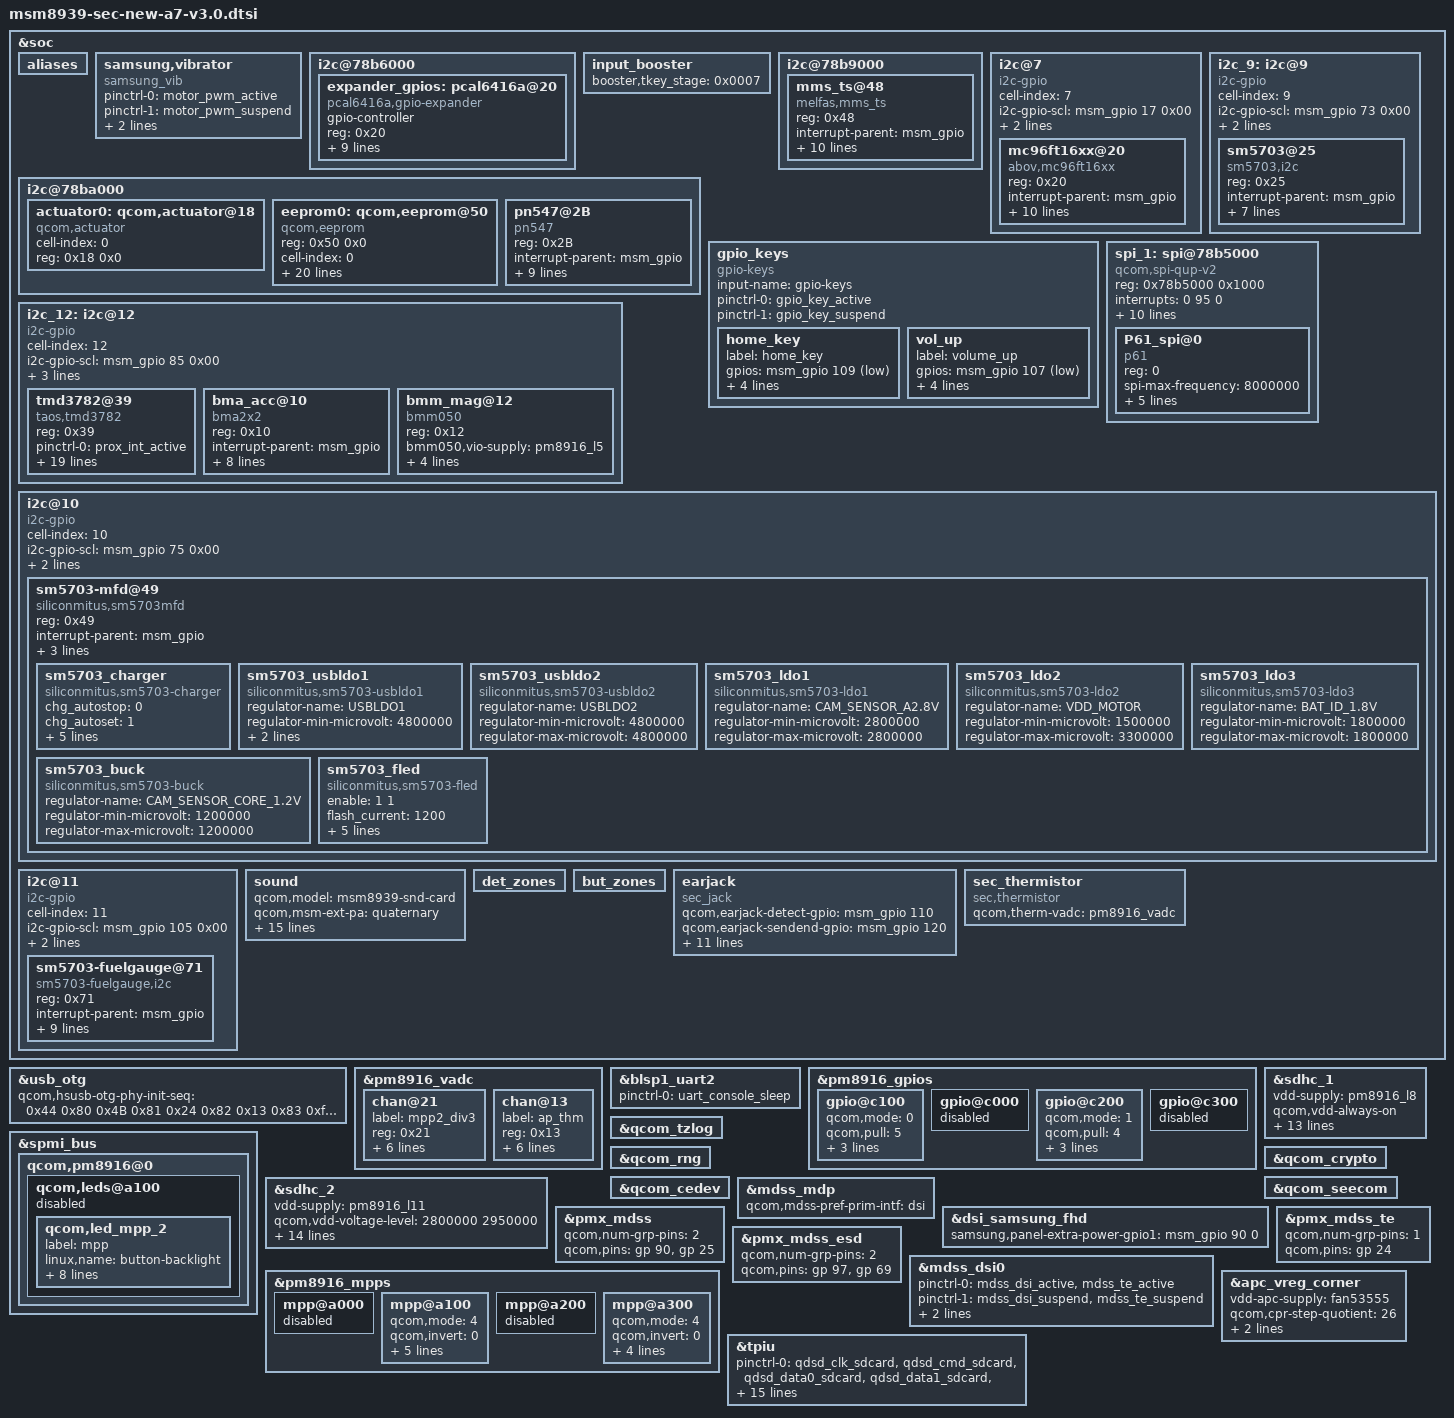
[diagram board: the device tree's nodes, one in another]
/* Copyright (c) 2014, The Linux Foundation. All rights reserved.
 *
 * This program is free software; you can redistribute it and/or modify
 * it under the terms of the GNU General Public License version 2 and
 * only version 2 as published by the Free Software Foundation.
 *
 * This program is distributed in the hope that it will be useful,
 * but WITHOUT ANY WARRANTY; without even the implied warranty of
 * MERCHANTABILITY or FITNESS FOR A PARTICULAR PURPOSE.  See the
 * GNU General Public License for more details.
 */

#include "msm8939-pinctrl-sec-a7-new-r00.dtsi"
#include "msm8939-camera.dtsi"
#include "msm8939-camera-sensor-cdp-a8-r07.dtsi"
#include "msm8939-sec-a7x-chn-battery-r00.dtsi"
#include "../../../../../../drivers/video/msm/mdss/samsung/S6E3FA3_AMS568HN01/dsi_panel_S6E3FA3_AMS568HN01_fhd_octa_cmd.dtsi"
#include "msm8939-a8lte_fingerprint-sensor_00.dtsi"

&soc {
	aliases {
	};

	samsung,vibrator {
		compatible = "samsung_vib";
		pinctrl-names = "tlmm_motor_active","tlmm_motor_suspend";
		pinctrl-0 = <&motor_pwm_active>;
		pinctrl-1 = <&motor_pwm_suspend>;
		samsung,vib_en = <&expander_gpios 15 0x1>;
		samsung,vib_pwm = <&msm_gpio 50 0x1>;
		status = "ok";
	};

	i2c@78b6000 { /* BLSP1 QUP2 */
		expander_gpios: pcal6416a@20 {
			compatible = "pcal6416a,gpio-expander";
			gpio-controller;
			#gpio-cells = <2>;
			reg = <0x20>;
			pinctrl-names = "expander_reset_setting";
			pinctrl-0 = <&expander_reset_active>;
			pcal6416a,gpio_start = <300>;
			pcal6416a,ngpio = <16>;
			pcal6416a,reset-gpio = <&msm_gpio 35 0x00>;
			pcal6416a,vdd-supply = <&pm8916_l5>;
			pcal6416a,support_initialize = <1>;
			/* config, 15 ~ 0, 1bit configure[1:input, 0:output]*/
			pcal6416a,config = <0x5FF0>;    /* 0101 1111 1111 0000 */
			/* data_out, 15 ~ 0, 1bit configure[1:high, 0:low]*/
			pcal6416a,data_out = <0x0004>;  /* 0000 0000 0000 0100  */
			/* pull_reg, 31 ~ 0, 2bit configure[00:no_pull, 01:pull_down, 10:pull_up, 11:not used]*/
			pcal6416a,pull_reg = <0x04000045>; /* 00 00 01 00 / 00 00 00 00 /  00 00 00 00 / 01 00 01 01 */
		};
	};

	input_booster {
		status = "okay";
		booster,tkey_stage = <0x0007>;
	};

	i2c@78b9000 { /* BLSP1 QUP5 */
		mms_ts@48 {
			compatible = "melfas,mms_ts";
			reg = <0x48>; /*slave address*/
			interrupt-parent = <&msm_gpio>;
			interrupts = <13 0>; /* Touch int gpio */
			pinctrl-names = "tsp_gpio_active", "tsp_gpio_suspend";
			pinctrl-0 = <&i2c_5_active &tsp_irq_default>;
			pinctrl-1 = <&i2c_5_sleep>;
			vdd-io-supply = <&pm8916_l6>;
			melfas,vdd_en = <&msm_gpio 89 0x1>;
			//melfas,io_en = <&msm_gpio 95 0x1>;
			melfas,irq-gpio = <&msm_gpio 13 0x00>; /*TSP IRQ GPIO */
			melfas,sda-gpio = <&msm_gpio 18 0x00>;
			melfas,scl-gpio = <&msm_gpio 19 0x00>;
			melfas,max_x = <2160>; /* <1080>; max x*/
			melfas,max_y = <3840>; /* <1920>; max y*/
		};
	};

	i2c@7 {
		cell-index = <7>;
                compatible = "i2c-gpio";
                i2c-gpio-scl = <&msm_gpio 17 0x00>;
                i2c-gpio-sda = <&msm_gpio 16 0x00>;
                i2c-gpio,delay-us = <5>;
                #address-cells = <1>;
                #size-cells = <0>;
		mc96ft16xx@20{
			compatible = "abov,mc96ft16xx";
			reg = <0x20>;
			interrupt-parent = <&msm_gpio>;
			interrupts = <114 0>;
			pinctrl-names = "touchkey_active", "touchkey_suspend";
			pinctrl-0 = <&touchkey_i2c_active &touchkey_int_active>;
			pinctrl-1 = <&touchkey_i2c_suspend &touchkey_int_suspend>;
			abov,sda-gpio = <&msm_gpio 16 0>;
			abov,scl-gpio = <&msm_gpio 17 0>;
			abov,irq-gpio = <&msm_gpio 114 0>;
			abov,tkey_en-gpio = <&msm_gpio 116 0>;
			//abov,tkey_led_en-gpio = <&msm_gpio 91 0>;
			vddo-supply = <&pm8916_l6>;
		};
	};

	i2c@78ba000 { /* BLSP1 QUP6 */
		status = "ok";

		actuator0: qcom,actuator@18 {
                        compatible = "qcom,actuator";
                        cell-index = <0>;
                        reg = <0x18 0x0>;
		};
                eeprom0: qcom,eeprom@50 {
                        compatible = "qcom,eeprom";
                        reg = <0x50 0x0>;
                        cell-index = <0>;
                        qcom,slave-addr = <0xB0>;
                        qcom,eeprom-name = "dw_dw9806b";
                        cam_vio-supply = <&pm8916_l16>;
                        qcom,cam-vreg-name = "cam_vio", "cam_vaf";
                        qcom,cam-vreg-type = <0 0>;
                        qcom,cam-vreg-min-voltage = <1800000 2800000>;
                        qcom,cam-vreg-max-voltage = <1800000 2800000>;
                        qcom,cam-vreg-op-mode = <1800000 100000>;
                        qcom,pvdd_is_en = <1>;
                        qcom,pvdd_en = <&expander_gpios 1 0>;
                        qcom,sensor-position = <0>;
                        qcom,cam-power-seq-type = "sensor_vreg", "sensor_vreg";
                        qcom,cam-power-seq-val = "cam_vaf", "cam_vio";
                        qcom,cam-power-seq-cfg-val = <1 1>;
                        qcom,cam-power-seq-delay =       <2 1>;
                        qcom,cal-num-blocks = <1>;
                        qcom,cal-page0 = <0 0 0 0 0 0>;
                        qcom,cal-poll0 = <0 0 0 0 0 0>;
                        qcom,cal-mem0 = <0x1200 0x00 2 0 1 0>;
                };

		pn547@2B {
			compatible = "pn547";
			reg = <0x2B>;
			interrupt-parent = <&msm_gpio>;
			interrupts = <51 0>;
			pinctrl-names = "nfc_active","nfc_suspend";
			pinctrl-0 = <&nfc_int_active >;
			pinctrl-1 = <&nfc_int_suspend>;
			pn547,firm-gpio = <&expander_gpios 3 0>;
			pn547,ven-gpio = <&expander_gpios 0 0>;
			pn547,irq-gpio = <&msm_gpio 51 0x01>;
			pn547,pwr_req = <&expander_gpios 2 0>;
			pn547,pvdd_en = <&expander_gpios 1 0>;
			clocks = <&clock_rpm clk_bb_clk2_pin>;
			clock-names = "nfc_clock";
		};
	};

	i2c_9:i2c@9 { /*SM5703 GPIO-I2C*/
		cell-index = <9>;
		compatible = "i2c-gpio";
		i2c-gpio-scl = <&msm_gpio 73 0x00>;
		i2c-gpio-sda = <&msm_gpio 72 0x00>;
		i2c-gpio,delay-us = <2>;
		#address-cells = <1>;
		#size-cells = <0>;

		sm5703@25{
			compatible = "sm5703,i2c";
			reg = <0x25>;
			interrupt-parent = <&msm_gpio>;
			interrupts= <12 0>;
			sm5703,irq-gpio = <&msm_gpio 12 0x00>;
			sm5703,gpio-sda = <&msm_gpio 72 0x00>;
			sm5703,gpio-scl = <&msm_gpio 73 0x00>;
			sm5703,uarton-gpio = <&msm_gpio 114 0x00>;
			pinctrl-names = "sm5703_i2c_active","sm5703_i2c_suspend";
			pinctrl-0 = <&muic_i2c_active &muic_int_pin>;
			pinctrl-1 = <&muic_i2c_suspend &muic_int_pin>;
		};
	};

	gpio_keys {
		compatible = "gpio-keys";
		input-name = "gpio-keys";
		pinctrl-names = "tlmm_gpio_key_active","tlmm_gpio_key_suspend";
		pinctrl-0 = <&gpio_key_active>;
		pinctrl-1 = <&gpio_key_suspend>;

		home_key {
			label = "home_key";
			gpios = <&msm_gpio 109 0x1>;
			linux,input-type = <1>;
			linux,code = <172>;
			gpio-key,wakeup;
			debounce-interval = <15>;
		};

		vol_up {
			label = "volume_up";
			gpios = <&msm_gpio 107 0x1>;
			linux,input-type = <1>;
			linux,code = <115>;
			gpio-key,wakeup;
			debounce-interval = <15>;
		};
	};

	spi_1: spi@78b5000 {  /* BLSP1 */
		compatible = "qcom,spi-qup-v2";
		#address-cells = <1>;
		#size-cells = <0>;
		reg-names = "spi_physical";
		reg = <0x78b5000 0x1000>;
		interrupt-names = "spi_irq";
		interrupts = <0 95 0>;
		spi-max-frequency = <18000000>;

		qcom,use-pinctrl;
		pinctrl-names = "default", "sleep";
		pinctrl-0 = <&spi1_default &spi1_cs_active>;
		pinctrl-1 = <&spi1_sleep &spi1_cs_sleep>;

		clocks = <&clock_gcc clk_gcc_blsp1_ahb_clk>,
			<&clock_gcc clk_gcc_blsp1_qup1_spi_apps_clk>;
		clock-names = "iface_clk", "core_clk";
		qcom,infinite-mode = <0>;
		qcom,ver-reg-exists;
		qcom,master-id = <86>;
		status = "ok";
		cell-index = <1>;

		P61_spi@0 {
			compatible = "p61";
			reg = <0>;
			spi-max-frequency = <8000000>;
			p61-mosipin = <&msm_gpio 0 0x0>;
			p61-misopin = <&msm_gpio 1 0x0>;
			p61-cspin = <&msm_gpio 2 0x0>;
			p61-clkpin = <&msm_gpio 3 0x0>;
			p61-test = <0xBB>;
		};
	};

	i2c_12: i2c@12 {
		cell-index = <12>;
		compatible = "i2c-gpio";
		i2c-gpio-scl = <&msm_gpio 85 0x00>;
		i2c-gpio-sda = <&msm_gpio 84 0x00>;
		i2c-gpio,delay-us = <2>;
		#address-cells = <1>;
		#size-cells = <0>;
		pinctrl-names = "default";
		pinctrl-0 = <&sensor_i2c_default>;
		tmd3782@39 {
			compatible = "taos,tmd3782";
			reg = <0x39>;
			pinctrl-names = "default";
			pinctrl-0 = <&prox_int_active>;
			pinctrl-1 = <&prox_int_suspend>;
			interrupt-parent = <&msm_gpio>;
			interrupts = <113 0>;
			reg_vio-supply = <&pm8916_l5>;
			reg_vdd-supply = <&pm8916_l17>;
			taos,irq_gpio = <&msm_gpio 113 0x1>;
			taos,prox_rawdata_trim = <170>;
			taos,prox_thresh_hi = <480>;
			taos,prox_thresh_low = <340>;
			taos,als_time = <0xEB>;
			taos,intr_filter = <0x33>;
			taos,prox_pulsecnt = <0x06>;
			taos,als_gain = <0x22>;
			taos,coef_atime = <50>;
			taos,ga = <97>;
			taos,coef_a = <1000>;
			taos,coef_b = <1880>;
			taos,coef_c = <642>;
			taos,coef_d = <1140>;
		};
		bma_acc@10 {
			compatible = "bma2x2";
			reg = <0x10>;
			interrupt-parent = <&msm_gpio>;
			interrupts = <115 0>;
			bma2x2,vio-supply = <&pm8916_l5>;
			bma2x2,gpio_int1 = <&msm_gpio 115 0x00>;
			bma2x2,fs_range = <0x00>;
			bma2x2,poll_interval = <100>;
			bma2x2,min_interval = <2>;
			bma2x2,supply_type = <1>;
			bma2x2,accel_place = <0>;
		};
		bmm_mag@12 {
			compatible = "bmm050";
			reg = <0x12>;
			bmm050,vio-supply = <&pm8916_l5>;
			bmm050,poll_interval = <100>;
			bmm050,min_interval = <13>;
			bmm050,fs_range = <0x60>;
			bmm050,magnetic_place = <0>;
		};
	};

	i2c@10 {
		cell-index = <10>;
		compatible = "i2c-gpio";
		i2c-gpio-scl = <&msm_gpio 75 0x00>;
		i2c-gpio-sda = <&msm_gpio 74 0x00>;
		i2c-gpio,delay-us = <5>;
		#address-cells = <1>;
		#size-cells = <0>;
		status = "okay";

		sm5703-mfd@49{
			compatible = "siliconmitus,sm5703mfd";
			reg = <0x49>;
			interrupt-parent = <&msm_gpio>;
			sm5703,irq-gpio = <&msm_gpio 62 0x00>;
			pinctrl-names = "default";
			pinctrl-0 = <&charger_int_active>;
			sm5703,mrstb-gpio = <&expander_gpios 12 0x00>;

			sm5703_charger {
				compatible = "siliconmitus,sm5703-charger";
				chg_autostop = <0>;
				chg_autoset = <1>;
				chg_aiclen = <1>;
				chg_aiclth = <4300>;
				fg_vol_val = <4350>;
				fg_soc_val = <95>;
				fg_curr_avr_val = <150>;
			};

			sm5703_usbldo1 {
				compatible = "siliconmitus,sm5703-usbldo1";
				regulator-name = "USBLDO1"; /* change name by yourself */
				regulator-min-microvolt = <4800000>;
				regulator-max-microvolt = <4800000>; /* max == min then apply_uV = 1 */
				/* regulator-microvolt-offset = < >; optional*/
				/* regulator-boot-on = "yes"; optional, exist = enabled */
				regulator-always-on = "yes";
				/* regulator-ramp-delay = <100>; optional*/
			};
			sm5703_usbldo2 {
				compatible = "siliconmitus,sm5703-usbldo2";
				regulator-name = "USBLDO2"; /* change name by yourself */
				regulator-min-microvolt = <4800000>;
				regulator-max-microvolt = <4800000>; /* max == min then apply_uV = 1 */
				/* regulator-microvolt-offset = < >; optional*/
				/* regulator-boot-on = "yes"; optional, exist = enabled */
				/* regulator-always-on = "yes"; optional, exist = enabled */
				/* regulator-ramp-delay = <100>; optional*/

			};
			sm5703_ldo1 {
				compatible = "siliconmitus,sm5703-ldo1";
				regulator-name = "CAM_SENSOR_A2.8V"; /* change name by yourself */
				regulator-min-microvolt = <2800000>;
				regulator-max-microvolt = <2800000>; /* max == min then apply_uV = 1 */
				/* regulator-microvolt-offset = < >; optional*/
				/* regulator-boot-on = "yes"; optional, exist = enabled */
				/* regulator-always-on = "yes"; optional, exist = enabled */
				/* regulator-ramp-delay = <100>; optional*/
			};

			sm5703_ldo2 {
				compatible = "siliconmitus,sm5703-ldo2";
				regulator-name = "VDD_MOTOR"; /* change name by yourself */
				regulator-min-microvolt = <1500000>;
				regulator-max-microvolt = <3300000>; /* max == min then apply_uV = 1 */
				/* regulator-microvolt-offset = < >; optional*/
				/* regulator-boot-on = "yes"; optional, exist = enabled */
				/* regulator-always-on = "yes"; optional, exist = enabled */
				/* regulator-ramp-delay = <100>; optional*/
			};

			sm5703_ldo3 {
				compatible = "siliconmitus,sm5703-ldo3";
				regulator-name = "BAT_ID_1.8V"; /* change name by yourself */
				regulator-min-microvolt = <1800000>;
				regulator-max-microvolt = <1800000>; /* max == min then apply_uV = 1 */
				/* regulator-microvolt-offset = < >; optional*/
				/* regulator-boot-on = "yes"; optional, exist = enabled */
				/* regulator-always-on = "yes"; optional, exist = enabled */
				/* regulator-ramp-delay = <100>; optional*/
			};

			sm5703_buck {
				compatible = "siliconmitus,sm5703-buck";
				regulator-name = "CAM_SENSOR_CORE_1.2V"; /* change name by yourself */
				regulator-min-microvolt = <1200000>;
				regulator-max-microvolt = <1200000>; /* max == min then apply_uV = 1 */
				/* regulator-microvolt-offset = < >; optional*/
				/* regulator-boot-on = "yes"; optional, exist = enabled */
				/* regulator-always-on = "yes"; optional, exist = enabled */
				/* regulator-ramp-delay = <100>; optional*/
			};

			sm5703_fled {
				compatible = "siliconmitus,sm5703-fled";
				enable = <1 1>;
				flash_current = <1200>;
				movie_current = <150>;
				sm5703,led1-gpio = <&msm_gpio 108 0x00>;
				sm5703,led2-gpio = <&msm_gpio 100 0x00>;
				pinctrl-names = "fled_default","fled_sleep";
				pinctrl-0 = <&cam_flash_active>;
				pinctrl-1 = <&cam_flash_sleep>;
			};
		};
	};

	i2c@11 {
		cell-index = <11>;
		compatible = "i2c-gpio";
		i2c-gpio-scl = <&msm_gpio 105 0x00>;
		i2c-gpio-sda = <&msm_gpio 106 0x00>;
		i2c-gpio,delay-us = <2>;
		#address-cells = <1>;
		#size-cells = <0>;

		sm5703-fuelgauge@71{
			compatible = "sm5703-fuelgauge,i2c";
			reg = <0x71>;
			interrupt-parent = <&msm_gpio>;
			pinctrl-names = "default";
			pinctrl-0 = <&fg_i2c_active &fuel_int_active>;
			fuelgauge,irqf = "IRQF_TRIGGER_FALLING + IRQF_ONESHOT + IRQF_NO_SUSPEND";
			fuelgauge,fuel_int = <&msm_gpio 121 0x1>;
			fuelgauge,fuel_alert_soc = <1>;
			fuelgauge,capacity_max = <1000>;
			fuelgauge,capacity_max_margin = <50>;
			fuelgauge,capacity_min = <0>;
			fuelgauge,capacity_calculation_type = <0x17>;
		};
	};

	sound {
		qcom,model = "msm8939-snd-card";
		qcom,msm-ext-pa = "quaternary";
		qcom,msm-mclk-freq = <9600000>;
		qcom,audio-routing =
			"RX_BIAS", "MCLK",
			"SPK_RX_BIAS", "MCLK",
			"INT_LDO_H", "MCLK",
			"MIC BIAS External", "Handset Mic",
			"MIC BIAS External", "Secondary Mic",
			"AMIC1", "MIC BIAS External",
			"AMIC2", "Headset Mic",
			"AMIC3", "MIC BIAS External";
		pinctrl-names = "cdc_lines_act",
				"cdc_lines_sus",
				"cross_conn_det_act",
				"cross_conn_det_sus",
				"cdc_lines_quat_ext_act",
				"cdc_lines_quat_ext_sus";
		pinctrl-0 = <&cdc_pdm_lines_act>;
		pinctrl-1 = <&cdc_pdm_lines_sus>;
		pinctrl-2 = <&cross_conn_det_act>;
		pinctrl-3 = <&cross_conn_det_sus>;
		pinctrl-4 = <&cdc_pdm_lines_act &ext_cdc_tlmm_lines_act>;
		pinctrl-5 = <&cdc_pdm_lines_sus &ext_cdc_tlmm_lines_sus>;
	};

	det_zones: det_zones {
		#list-det-cells = <4>;
	};

	but_zones: but_zones {
		#list-but-cells = <3>;
	};

	earjack {
		compatible = "sec_jack";
		qcom,earjack-detect-gpio = <&msm_gpio 110 0x0>;
		qcom,earjack-sendend-gpio = <&msm_gpio 120 0x0>;
		qcom,earjack-read-vadc = <&pm8916_vadc>;

		det-zones-list = <&det_zones 0 10000 10 0>,
						 <&det_zones 980 10000 10 0>,
						 <&det_zones 1057 10000 10 1>,
						 <&det_zones 9999 10000 10 1>;
		but-zones-list = <&but_zones 0 1 309>,
				 <&but_zones 3 310 356>,
				 <&but_zones 1 357 480>,
				 <&but_zones 2 481 999>;
		mpp-channel-scaling = <2 1 3>;
		pinctrl-names = "earjack_gpio_active","earjack_gpio_suspend";
		pinctrl-0 = <&earjack_det_act &earjack_switch_act>;
		pinctrl-1 = <&earjack_det_sus &earjack_switch_sus>;
	};

	sec_thermistor {
		compatible = "sec,thermistor";
		qcom,therm-vadc = <&pm8916_vadc>;
	};
};

&usb_otg {
        qcom,hsusb-otg-phy-init-seq =
                        <0x44 0x80 0x4B 0x81 0x24 0x82 0x13 0x83 0xffffffff>;
};

&pm8916_vadc {
	chan@21 {
		label = "mpp2_div3";
		reg = <0x21>; // channel for MPP2 , 1:3scale
		qcom,decimation = <0>;
		qcom,pre-div-channel-scaling = <1>; // 1:3scale
		qcom,calibration-type = "absolute";
		qcom,scale-function = <0>;
		qcom,hw-settle-time = <1>;
		qcom,fast-avg-setup = <0>;
	};
};

&blsp1_uart2 {
	status = "ok";
	pinctrl-names = "default";
	pinctrl-0 = <&uart_console_sleep>;
};

&pm8916_gpios {
	gpio@c100 { /* GPIO 2 */
		/* NFC_CLK_REQ */
		qcom,mode = <0>; /* QPNP_PIN_MODE_DIG_IN */
		qcom,pull = <5>; /* QPNP_PIN_PULL_NO */
		qcom,vin-sel = <2>; /* QPNP_PIN_VIN2 */
		qcom,src-sel = <2>; /* QPNP_PIN_SEL_FUNC_1 */
		qcom,master-en = <1>;
	};
};
&spmi_bus {
	qcom,pm8916@0 {
		qcom,leds@a100 {
			status = "disabled";
			qcom,led_mpp_2 {
				label = "mpp";
				linux,name = "button-backlight";
				linux,default-trigger = "none";
				qcom,default-state = "off";
				qcom,max-current = <40>;
				qcom,current-setting = <5>;
				qcom,id = <6>;
				qcom,mode = "manual";
				qcom,source-sel = <1>;
				qcom,mode-ctrl = <0x60>;
			};
		};
	};
};

&sdhc_1 {
	vdd-supply = <&pm8916_l8>;
	qcom,vdd-always-on;
	qcom,vdd-lpm-sup;
	qcom,vdd-voltage-level = <2900000 2900000>;
	qcom,vdd-current-level = <200 400000>;

	vdd-io-supply = <&pm8916_l5>;
	qcom,vdd-io-always-on;
	qcom,vdd-io-lpm-sup;
	qcom,vdd-io-voltage-level = <1800000 1800000>;
	qcom,vdd-io-current-level = <200 60000>;

	pinctrl-names = "active", "sleep";
	pinctrl-0 = <&sdc1_clk_on &sdc1_cmd_on &sdc1_data_on>;
	pinctrl-1 = <&sdc1_clk_off &sdc1_cmd_off &sdc1_data_off>;

	qcom,nonremovable;

	status = "ok";
};

&sdhc_2 {
	vdd-supply = <&pm8916_l11>;
	qcom,vdd-voltage-level = <2800000 2950000>;
	qcom,vdd-current-level = <15000 400000>;

	vdd-io-supply = <&pm8916_l12>;
	qcom,vdd-io-voltage-level = <1800000 2950000>;
	qcom,vdd-io-current-level = <200 50000>;

	pinctrl-names = "active", "sleep";
	pinctrl-0 = <&sdc2_clk_on &sdc2_cmd_on &sdc2_data_on &sdc2_cd_on>;
	pinctrl-1 = <&sdc2_clk_off &sdc2_cmd_off &sdc2_data_off &sdc2_cd_off>;

	#address-cells = <0>;
	interrupt-parent = <&sdhc_2>;
	interrupts = <0 1 2>;
	#interrupt-cells = <1>;
	interrupt-map-mask = <0xffffffff>;
	interrupt-map = <0 &intc 0 125 0
			1 &intc 0 221 0
			2 &msm_gpio 38 0>;
	interrupt-names = "hc_irq", "pwr_irq", "status_irq";
	cd-gpios = <&msm_gpio 38 0x1>;

	status = "ok";
};

&qcom_tzlog {
	status = "okay";
};

&qcom_rng {
	status = "okay";
};

&qcom_crypto {
	status = "okay";
};

&qcom_cedev {
	status = "okay";
};

&qcom_seecom {
	status = "okay";
};

&mdss_mdp {
	qcom,mdss-pref-prim-intf = "dsi";
};

&dsi_samsung_fhd {
	//qcom,esd_irq_gpio = <&msm_gpio 49 0>;
	//qcom,esd-check-enabled;

	samsung,panel-extra-power-gpio1 = <&msm_gpio 90 0>;
	//samsung,panel-extra-power-gpio2 = <&msm_gpio 87 0>;
};

&pmx_mdss {
	qcom,num-grp-pins = <2>;
	qcom,pins = <&gp 90>, <&gp 25>;
};

&pmx_mdss_te {
	qcom,num-grp-pins = <1>;
	qcom,pins = <&gp 24>;
};

&pmx_mdss_esd {
	qcom,num-grp-pins = <2>;
	qcom,pins = <&gp 97>, <&gp 69>;
};

&mdss_dsi0 {
	pinctrl-names = "mdss_default", "mdss_sleep";
	pinctrl-0 = <&mdss_dsi_active &mdss_te_active>;
	pinctrl-1 = <&mdss_dsi_suspend &mdss_te_suspend>;
	qcom,dsi-pref-prim-pan = <&dsi_samsung_fhd>;

	qcom,platform-reset-gpio = <&msm_gpio 25 0>;
};

&pm8916_mpps {
	mpp@a000 { /* MPP 1 */
		/* VDD_PX */
		status = "disabled";
	};

	mpp@a100 { /* MPP 2 */
		status = "ok";
		qcom,mode = <4>; // AIN input
		qcom,invert = <0>; //No Invert
		qcom,output-type = <0>; //CMOS
		qcom,vin-sel = <2>; //PM8971_S3 1.8v
		qcom,src-sel = <0>; //MPP Constant
		qcom,ain-route = <1>; // QPNP_PIN_AIN_AMUX_CH6 = 1 for MPP2
		qcom,master-en = <1>; // Function constant
	};

	mpp@a200 { /* MPP 3 */
		/* VREF DAC */
		status = "disabled";
	};

	mpp@a300 { /* MPP 4 */
		status = "ok";
		qcom,mode = <4>; // AIN input
		qcom,invert = <0>; //No Invert
		qcom,output-type = <0>; //CMOS
		qcom,src-sel = <0>; //MPP Constant
		qcom,ain-route = <3>; // QPNP_PIN_AIN_AMUX_CH8 = 3 for MPP4
		qcom,master-en = <1>; // Function constant
	};
};

&pm8916_gpios {
	gpio@c000 { /* GPIO 1 */
		/* Battery UICC Alarm */
		status = "disabled";
	};

	gpio@c100 { /* GPIO 2 */
		/* NFC_CLK_REQ */
		qcom,mode = <0>; /* QPNP_PIN_MODE_DIG_IN */
		qcom,pull = <5>; /* QPNP_PIN_PULL_NO */
		qcom,vin-sel = <2>; /* QPNP_PIN_VIN2 */
		qcom,src-sel = <2>; /* QPNP_PIN_SEL_FUNC_1 */
		qcom,master-en = <1>;
	};

	gpio@c200 { /* GPIO 3 */
		/* External regulator control for WTR */
		qcom,mode = <1>; /* QPNP_PIN_MODE_DIG_OUT */
		qcom,pull = <4>; /* QPNP_PIN_PULL_DOWN */
		qcom,vin-sel = <3>; /* QPNP_PIN_VIN2 */
		qcom,src-sel = <0>; /* QPNP_PIN_SEL_GPIO */
		qcom,master-en = <1>;
	};

	gpio@c300 { /* GPIO 4 */
		/* External regulator control for APC */
		status = "disabled";
	};
};

/* CoreSight */
&tpiu {
	pinctrl-names = "sdcard", "trace", "swduart",
			"swdtrc", "jtag", "spmi";
	/* NIDnT */
	pinctrl-0 = <&qdsd_clk_sdcard &qdsd_cmd_sdcard
		     &qdsd_data0_sdcard &qdsd_data1_sdcard
		     &qdsd_data2_sdcard &qdsd_data3_sdcard>;
	pinctrl-1 = <&qdsd_clk_trace &qdsd_cmd_trace
		     &qdsd_data0_trace &qdsd_data1_trace
		     &qdsd_data2_trace &qdsd_data3_trace>;
	pinctrl-2 = <&qdsd_cmd_swduart &qdsd_data0_swduart
		     &qdsd_data1_swduart &qdsd_data2_swduart
		     &qdsd_data3_swduart>;
	pinctrl-3 = <&qdsd_clk_swdtrc &qdsd_cmd_swdtrc
		     &qdsd_data0_swdtrc &qdsd_data1_swdtrc
		     &qdsd_data2_swdtrc &qdsd_data3_swdtrc>;
	pinctrl-4 = <&qdsd_cmd_jtag &qdsd_data0_jtag
		     &qdsd_data1_jtag &qdsd_data2_jtag
		     &qdsd_data3_jtag>;
	pinctrl-5 = <&qdsd_clk_spmi &qdsd_cmd_spmi
		     &qdsd_data0_spmi &qdsd_data3_spmi>;
};

&pm8916_vadc {
	chan@13 {
		label = "ap_thm";
		reg = <0x13>; // channel 19 for MPP4 , 1:1scale
		qcom,decimation = <0>;
		qcom,pre-div-channel-scaling = <0>; // 1:1scale
		qcom,calibration-type = "ratiometric";
		qcom,scale-function = <1>;
		qcom,hw-settle-time = <2>;
		qcom,fast-avg-setup = <0>;
	};
};

&apc_vreg_corner {
	vdd-apc-supply = <&fan53555>;
	qcom,cpr-step-quotient = <26>;
	qcom,cpr-apc-volt-step = <12500>;
	qcom,cpr-up-threshold = <2>;
};
